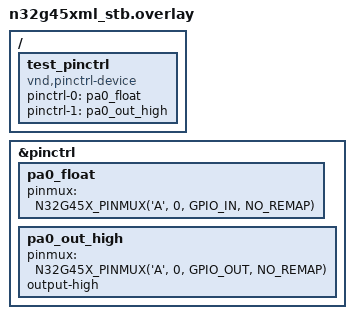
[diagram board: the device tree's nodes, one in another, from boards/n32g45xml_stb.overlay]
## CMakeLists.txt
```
# Copyright (c) 2024 Nations Technologies Inc.
# SPDX-License-Identifier: Apache-2.0

cmake_minimum_required(VERSION 3.28.0)
find_package(Zephyr REQUIRED HINTS $ENV{ZEPHYR_BASE})

project(pinctrl_nsing_l3)

# Custom state "drive" from pinctrl-names ("default", "drive"): the
# framework numbers private states from PINCTRL_STATE_PRIV_START on,
# in pinctrl-names order, so "drive" gets id 2. Only "default" and
# "sleep" have framework-defined macros; custom ones must be defined
# by the user (see tests/drivers/pinctrl/api). Injected as a compile
# definition so the shared ../common/test_device.c sees it too.
target_compile_definitions(app PRIVATE PINCTRL_STATE_DRIVE=PINCTRL_STATE_PRIV_START)

target_sources(app PRIVATE ../common/test_device.c)
target_sources(app PRIVATE src/main.c)
```

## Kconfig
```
# Copyright (c) 2024 Nations Technologies Inc.
# SPDX-License-Identifier: Apache-2.0

mainmenu "pinctrl N32G45x L3 Functional Test"

source "Kconfig.zephyr"

config PINCTRL_TEST_NON_STATIC
	bool "Access to pin control configuration"
	select PINCTRL_NON_STATIC
	help
	  This option should be selected by unit tests that need to access the pin
	  control configuration defined in a device driver.
```

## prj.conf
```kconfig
# Copyright (c) 2024 Nations Technologies Inc.
# SPDX-License-Identifier: Apache-2.0

CONFIG_ZTEST=y
CONFIG_PINCTRL_TEST_NON_STATIC=y

# Tested subsystems only: pinctrl and GPIO, no other peripherals
CONFIG_I2C=n
```

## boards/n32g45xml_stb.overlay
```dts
/*
 * Copyright (c) 2024 Nations Technologies Inc.
 *
 * SPDX-License-Identifier: Apache-2.0
 */

#include <zephyr/dt-bindings/pinctrl/n32g45x-pinctrl.h>

/*
 * L3 functional pinctrl test device: PA0 switches between a floating
 * input ("default") and a push-pull output high ("drive") state through
 * the full pinctrl framework (pinctrl_apply_state -> driver). The
 * resulting level is observed on PA2 through the PA0 -> PA2 jumper
 * wire. PA0/PA2 do not conflict with board resources (USART1 PA9/PA10,
 * I2C1 PB6/PB7, LEDs PA8/PB4/PB5, SWD PA13-15).
 */
/ {
	test_pinctrl: test_pinctrl {
		compatible = "vnd,pinctrl-device";
		pinctrl-0 = <&pa0_float>;
		pinctrl-1 = <&pa0_out_high>;
		pinctrl-names = "default", "drive";
	};
};

&pinctrl {
	pa0_float: pa0_float {
		pinmux = <N32G45X_PINMUX('A', 0, GPIO_IN, NO_REMAP)>;
	};

	pa0_out_high: pa0_out_high {
		pinmux = <N32G45X_PINMUX('A', 0, GPIO_OUT, NO_REMAP)>;
		output-high;
	};
};
```

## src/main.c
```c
/*
 * Copyright (c) 2024 Nations Technologies Inc.
 *
 * SPDX-License-Identifier: Apache-2.0
 */

#include <zephyr/drivers/gpio.h>
#include <zephyr/drivers/pinctrl.h>
#include <zephyr/kernel.h>
#include <zephyr/ztest.h>

#include <n32g45x.h>

/*
 * L3 functional pinctrl test: switch PA0 between two DT-defined states
 * through the complete framework path (pinctrl_apply_state -> driver
 * configure_pins), asserting both the register writes and - through the
 * PA0 -> PA2 jumper wire - the real level seen at the pin. Requires the
 * jumper (same fixture as the GPIO L3 suite).
 */
#define TEST_PINCTRL DT_NODELABEL(test_pinctrl)
PINCTRL_DT_DEV_CONFIG_DECLARE(TEST_PINCTRL);
static const struct pinctrl_dev_config *pcfg =
	PINCTRL_DT_DEV_CONFIG_GET(TEST_PINCTRL);

#define GPIOA_DEV DEVICE_DT_GET(DT_NODELABEL(gpioa))
#define OUT_PIN 0U
#define OBS_PIN 2U /* PA2, jumper to PA0 */

ZTEST(pinctrl_l3, test_state_switch)
{
	/* PA2 pull-down input: reads what PA0 drives through the wire
	 * (0 when PA0 is floating, 1 when driven high).
	 */
	zassert_ok(gpio_pin_configure(GPIOA_DEV, OBS_PIN,
				      GPIO_INPUT | GPIO_PULL_DOWN));

	/* "default": PA0 floating input */
	zassert_ok(pinctrl_apply_state(pcfg, PINCTRL_STATE_DEFAULT));
	zassert_equal(GPIOA->PL_CFG & 0xF, 0x4); /* CNFMODE: floating input */
	zassert_equal((GPIOA->POD >> OUT_PIN) & 0x1, 0);
	k_busy_wait(200);
	zassert_equal((GPIOA->PID >> OBS_PIN) & 0x1, 0); /* high-Z -> 0 */

	/* "drive": PA0 push-pull output, initial high (output-high prop).
	 * CNFMODE = PCFG 00 (GP push-pull) | PMODE 01 (2MHz) = 0x1: the
	 * pinctrl driver picks PMODE from the slew-rate property, which
	 * defaults to "2mhz" - not the GPIO driver's 50MHz default.
	 */
	zassert_ok(pinctrl_apply_state(pcfg, PINCTRL_STATE_DRIVE));
	zassert_equal(GPIOA->PL_CFG & 0xF, 0x1); /* CNFMODE: GP PP 2MHz */
	zassert_equal((GPIOA->POD >> OUT_PIN) & 0x1, 1); /* POD = 1 */
	k_busy_wait(200);
	zassert_equal((GPIOA->PID >> OBS_PIN) & 0x1, 1); /* driven high -> 1 */

	/* back to "default": floating again */
	zassert_ok(pinctrl_apply_state(pcfg, PINCTRL_STATE_DEFAULT));
	k_busy_wait(200);
	zassert_equal((GPIOA->PID >> OBS_PIN) & 0x1, 0);
}

ZTEST_SUITE(pinctrl_l3, NULL, NULL, NULL, NULL, NULL);
```
